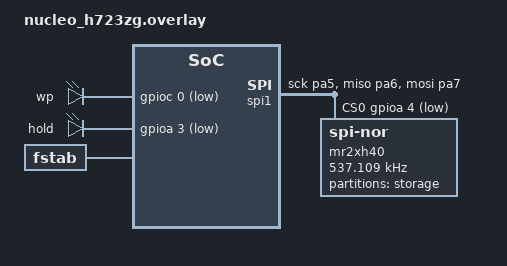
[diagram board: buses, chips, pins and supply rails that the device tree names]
/*
 * Copyright (c) 2023 aris-space
 * SPDX-License-Identifier: Apache-2.0
 */

/* This devicetree overlay file will be automatically picked by the Zephyr
 * build system when building the sample for the nucleo_h723zg board. It shows
 * how the example-application can be built on sample boards already provided
 * by Zephyr.
 */


/ {
    aliases {
        spi-flash0 = &mr2xh40;
        spi-nhold = &hold;
        spi-nwp = &wp;
    };
};

&spi1 {

    status = "okay";
    pinctrl-0 = <&spi1_sck_pa5 &spi1_miso_pa6 &spi1_mosi_pa7>;
    pinctrl-names = "default";
    cs-gpios = <&gpioa 4 GPIO_ACTIVE_LOW>;

    mr2xh40: mr2xh40@0 {
        compatible = "jedec,spi-nor";
        status = "okay";
        reg = <0>;
        spi-max-frequency = <537109>;
        size = <0x400000>;
        has-dpd;
        t-enter-dpd = <3000>;
        t-exit-dpd = <400000>;
        jedec-id = [00 00 00];
    };
};


/ {
    leds {
        compatible = "gpio-leds";
        wp: wp_0 {
            gpios = <&gpioc 0 GPIO_ACTIVE_LOW>;
        };

        hold: hold_1 {
            gpios = <&gpioa 3 GPIO_ACTIVE_LOW>;
        };
    };
};

&mr2xh40 {
    partitions {
        compatible = "fixed-partitions";
        #address-cells = <1>;
        #size-cells = <1>;
        storage_partition: partition@0 {
            label = "storage";
        //lfs1_partition: partition@0 {
        //  label = "lfs1_partition";
            // reg = <0x0 0x40000>;
            reg = <0x0 0x80000>;
        };
    };
};

/ {
    fstab {
        compatible = "zephyr,fstab";
        lfs1: lfs1 {
            compatible = "zephyr,fstab,littlefs";
            mount-point = "/seq";
            partition = <&storage_partition>;

            /* When changing these values, make sure to also changed
             * their counterparts in Kconfig. Because buffers are
             * allocated at compile time, they need to match.
             */
            
            read-size = <16>;
            prog-size = <16>;
            cache-size = <64>;
            lookahead-size = <32>;
            block-cycles = <512>;
        };
    };
};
